# PIC32CK1025SG01064 register map
Vendor: Microchip Technology; Series: PIC32CKSG01; File version: 0
CPU: CM33 r0p0, little endian, MPU, FPU, DSP, 3 interrupt priority bits, 158 interrupts, 19 SAU regions
Registers are 32-bit, read-write, reset 0x0 unless marked. A register's access mark holds for its fields unless they carry their own. Offsets are from the block's base; [hi:lo] are bit positions; {n}, {i} and the like mark numbered series; 'fields as' and 'values as' point back to an identical list.

## CoreDebug — Debug Control Block
Base 0xE000EDF0
Same registers: CoreDebug_NS 0xE002EDF0
0x00 DHCSR — Debug Halting Control and Status Register
  [26] S_RESTART_ST ro — Restart sticky status
  [25] S_RESET_ST ro — Reset sticky status
  [24] S_RETIRE_ST ro — Retire sticky status
  [23] S_FPD ro — Floating-point registers Debuggable
  [22] S_SUIDE ro — Secure unprivileged-only halting debug enabled
  [21] S_NSUIDE ro — Non-secure unprivileged-only haltingdebug enabled
  [20] S_SDE ro — Secure debug enabled
  [19] S_LOCKUP ro — Lockup status
  [18] S_SLEEP ro — Sleeping status
  [17] S_HALT ro — Halted status
  [16] S_REGRDY ro — Register ready status
  [31:16] DBGKEY wo — Debug key, must write 0xA05F to enable writes
  [6] C_PMOV — Halt on PMU overflow contro
  [5] C_SNAPSTALL — Snap stall control
  [3] C_MASKINTS — Mask PendSV, SysTick and external configurable interrupts
  [2] C_STEP — Enable single step
  [1] C_HALT — Halt processor
  [0] C_DEBUGEN — Enable Halting debug
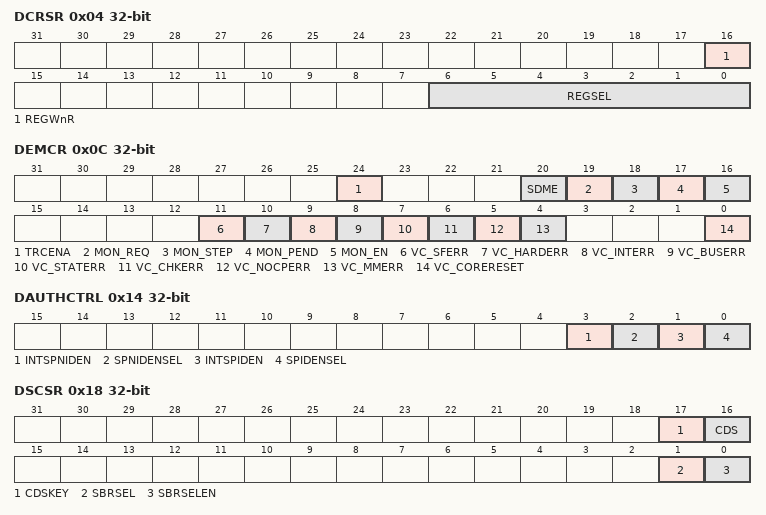
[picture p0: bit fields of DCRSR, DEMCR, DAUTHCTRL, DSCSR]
0x04 DCRSR wo — Debug Core Register Select Register
  [16] REGWnR — Register write/not-read access
  [6:0] REGSEL — Register selector
0x08 DCRDR — Debug Core Register Data Register
  [31:0] DBGTMP — Data temporary buffer
0x0C DEMCR — Debug Exception and Monitor Control Register
  [24] TRCENA — Global DWT and ITM features enable
  [20] SDME — Secure DebugMonitor enable
  [19] MON_REQ — DebugMonitor semaphore bit
  [18] MON_STEP — Enable DebugMonitor stepping
  [17] MON_PEND — DebugMonitor pending state
  [16] MON_EN — DebugMonitor enable
  [11] VC_SFERR — SecureFault exception Halting debug vector catch enable
  [10] VC_HARDERR — HardFault exception Halting debug vector catch enable
  [9] VC_INTERR — Exception entry and return faults Halting debug vector catch enable
  [8] VC_BUSERR — BusFault exception Halting debug vector catch enable
  [7] VC_STATERR — UsageFault exception state information error Halting debug vector catch enable
  [6] VC_CHKERR — UsageFault exception checking error Halting debug vector catch enable
  [5] VC_NOCPERR — UsageFault exception coprocessor access Halting debug vector catch enable
  [4] VC_MMERR — MemManage exception Halting debug vector catch enable
  [0] VC_CORERESET — Core reset Halting debug vector catch enable
0x14 DAUTHCTRL — Debug Authentication Control Register
  [3] INTSPNIDEN — Internal Secure non-invasive debug enable
  [2] SPNIDENSEL — Secure non-invasive debug enable select
  [1] INTSPIDEN — Internal Secure invasive debug enable
  [0] SPIDENSEL — Secure invasive debug enable select
0x18 DSCSR — Debug Security Control and Status Register
  [17] CDSKEY — CDS field write-enable key
  [16] CDS — Current domain Secure
  [1] SBRSEL — Secure Banked register select
  [0] SBRSELEN — Secure Banked register select enable

## EIC — External Interrupt Controller
Base 0x4401A000
Same registers: EIC_SEC 0x4401B000
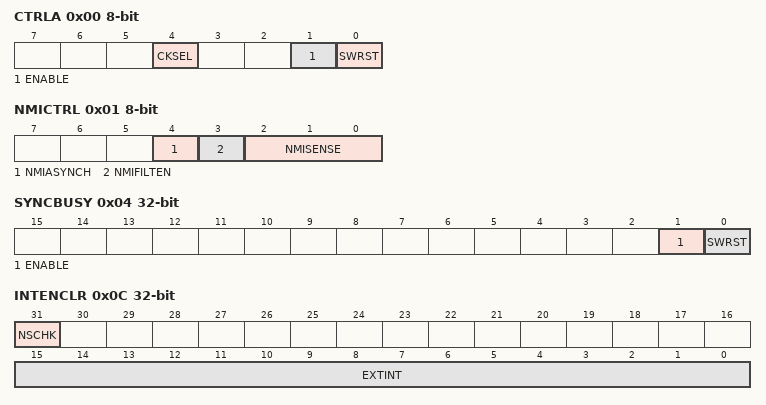
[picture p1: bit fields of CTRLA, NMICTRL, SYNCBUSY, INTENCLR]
0x00 CTRLA 8-bit — Control A
  [4] CKSEL — Clock Selection
    0=CLK_GCLK (Clocked by GCLK); 1=CLK_ULP32K (Clocked by ULP32K)
  [1] ENABLE
  [0] SWRST — Software Reset
0x01 NMICTRL 8-bit — Non-Maskable Interrupt Control
  [4] NMIASYNCH — Asynchronous Edge Detection Mode
    0=SYNC (Edge detection is clock synchronously operated); 1=ASYNC (Edge detection is clock asynchronously operated)
  [3] NMIFILTEN — Non-Maskable Interrupt Filter Enable
  [2:0] NMISENSE — Non-Maskable Interrupt Sense Configuration
    0=NONE (No detection); 1=RISE (Rising-edge detection); 2=FALL (Falling-edge detection); 3=BOTH (Both-edges detection); 4=HIGH (High-level detection); 5=LOW (Low-level detection)
0x02 NMIFLAG 16-bit write-1-clears — Non-Maskable Interrupt Flag Status and Clear
  [0] NMI — Non-Maskable Interrupt
0x04 SYNCBUSY ro — Synchronization Busy
  [1] ENABLE — Enable Synchronization Busy Status
  [0] SWRST — Software Reset Synchronization Busy Status
0x08 EVCTRL — Event Control
  [15:0] EXTINTEO — External Interrupt Event Output Enable
0x0C INTENCLR write-1-clears — Interrupt Enable Clear
  [31] NSCHK — Non-secure Check Interrupt Enable
  [15:0] EXTINT — External Interrupt Enable
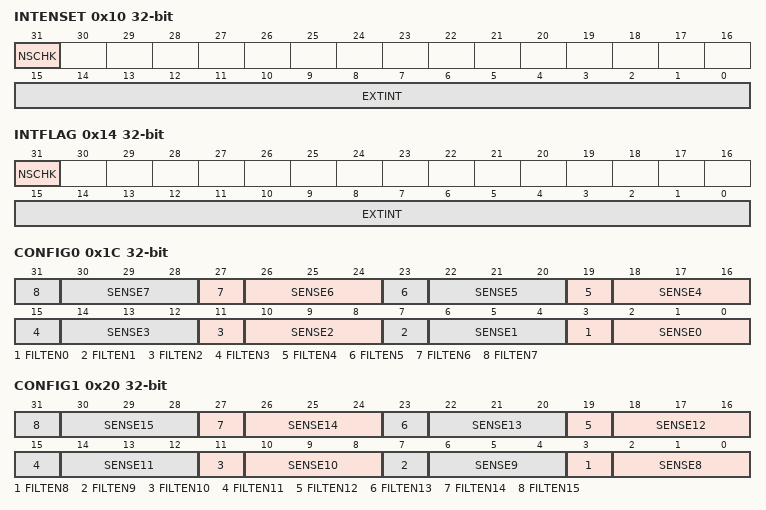
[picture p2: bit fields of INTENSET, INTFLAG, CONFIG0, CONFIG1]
0x10 INTENSET write-1-sets — Interrupt Enable Set
  fields as INTENCLR
0x14 INTFLAG write-1-clears — Interrupt Flag Status and Clear
  [31] NSCHK — Non-secure Check Interrupt
  [15:0] EXTINT — External Interrupt
0x18 ASYNCH — External Interrupt Asynchronous Mode
  [15:0] ASYNCH — Asynchronous Edge Detection Mode
    values as NMICTRL.NMIASYNCH
0x1C CONFIG0 — External Interrupt Sense Configuration
  [4n+3] FILTEN{n} (n=0..7) — Filter Enable {n}
  [4n+2:4n] SENSE{n} (n=0..7) — Input Sense Configuration {n}
    0=NONE (No detection); 1=RISE (Rising edge detection); 2=FALL (Falling edge detection); 3=BOTH (Both edges detection); 4=HIGH (High level detection); 5=LOW (Low level detection)
0x20 CONFIG1 — External Interrupt Sense Configuration
  [4n-29] FILTEN{n} (n=8..15) — Filter Enable {n}
  [4n-30:4n-32] SENSE{n} (n=8..15) — Input Sense Configuration {n}
    values as CONFIG0.SENSE0
0x30 DEBOUNCEN — Debouncer Enable
  [15:0] DEBOUNCEN
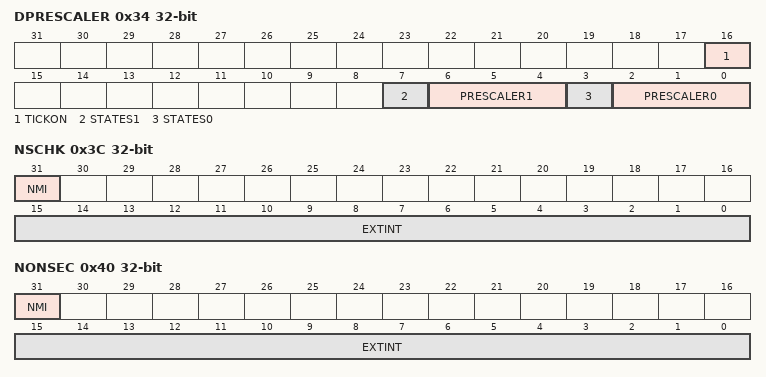
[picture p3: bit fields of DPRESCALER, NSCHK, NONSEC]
0x34 DPRESCALER — Debouncer Prescaler
  [16] TICKON — Pin Sampler frequency selection
    0=CLK_GCLK_EIC (Clocked by GCLK); 1=CLK_LFREQ (Clocked by Low Frequency Clock)
  [7] STATES1 — Debouncer number of states
    0=LFREQ3 (3 low frequency samples); 1=LFREQ7 (7 low frequency samples)
  [6:4] PRESCALER1 — Debouncer Prescaler
    0=DIV2 (EIC clock divided by 2); 1=DIV4 (EIC clock divided by 4); 2=DIV8 (EIC clock divided by 8); 3=DIV16 (EIC clock divided by 16); 4=DIV32 (EIC clock divided by 32); 5=DIV64 (EIC clock divided by 64); 6=DIV128 (EIC clock divided by 128); 7=DIV256 (EIC clock divided by 256)
  [3] STATES0 — Debouncer number of states
    values as STATES1
  [2:0] PRESCALER0 — Debouncer Prescaler
    values as PRESCALER1
0x38 PINSTATE ro
  [15:0] PINSTATE
0x3C NSCHK — Non-secure Interrupt Check Enable
  [31] NMI — Non-Maskable External Interrupt Nonsecure Check Enable
  [15:0] EXTINT — External Interrupt Nonsecure Check Enable
0x40 NONSEC — Non-secure Interrupt
  [31] NMI — Non-Maskable Interrupt Nonsecure Enable
  [15:0] EXTINT — External Interrupt Nonsecure Enable

## Notices in the file
Copyright (c) 2026 Microchip Technology Inc.
SPDX-License-Identifier: Apache-2.0
Licensed under the Apache License, Version 2.0 (the "License");
you may not use this file except in compliance with the License.
You may obtain a copy of the License at
http://www.apache.org/licenses/LICENSE-2.0
Unless required by applicable law or agreed to in writing, software
distributed under the License is distributed on an "AS IS" BASIS,
WITHOUT WARRANTIES OR CONDITIONS OF ANY KIND, either express or implied.
See the License for the specific language governing permissions and
limitations under the License.
